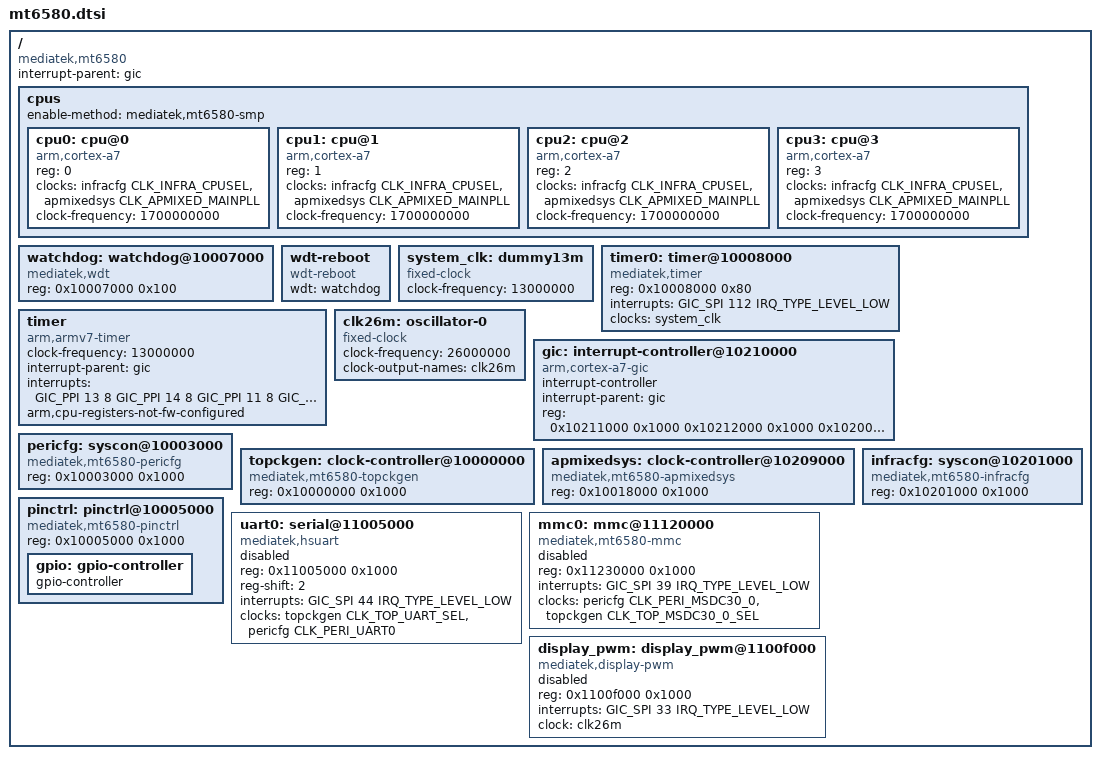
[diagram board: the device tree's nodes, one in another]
#include <dt-bindings/clock/mt6580-clk.h>
#include <dt-bindings/gpio/gpio.h>
#include <dt-bindings/interrupt-controller/irq.h>
#include <dt-bindings/interrupt-controller/arm-gic.h>
#include <dt-bindings/phy/phy.h>
#include <dt-bindings/power/mt6580-power.h>
#include <dt-bindings/reset/mt6580-reset.h>
#include "skeleton.dtsi"

/ {
    compatible = "mediatek,mt6580";
    interrupt-parent = <&gic>;
    #address-cells = <1>;
    #size-cells = <1>;

    cpus {
        #address-cells = <1>;
        #size-cells = <0>;
        enable-method = "mediatek,mt6580-smp";

        cpu0: cpu@0 {
            device_type = "cpu";
            compatible = "arm,cortex-a7";
            reg = <0>;
            clocks = <&infracfg CLK_INFRA_CPUSEL>,
                    <&apmixedsys CLK_APMIXED_MAINPLL>;
            clock-names = "cpu", "intermediate";
            clock-frequency = <1700000000>;
        };

        cpu1: cpu@1 {
            device_type = "cpu";
            compatible = "arm,cortex-a7";
            reg = <1>;
            clocks = <&infracfg CLK_INFRA_CPUSEL>,
                    <&apmixedsys CLK_APMIXED_MAINPLL>;
            clock-names = "cpu", "intermediate";
            clock-frequency = <1700000000>;
        };

        cpu2: cpu@2 {
            device_type = "cpu";
            compatible = "arm,cortex-a7";
            reg = <2>;
            clocks = <&infracfg CLK_INFRA_CPUSEL>,
                    <&apmixedsys CLK_APMIXED_MAINPLL>;
            clock-names = "cpu", "intermediate";
            clock-frequency = <1700000000>;
        };

        cpu3: cpu@3 {
            device_type = "cpu";
            compatible = "arm,cortex-a7";
            reg = <3>;
            clocks = <&infracfg CLK_INFRA_CPUSEL>,
                    <&apmixedsys CLK_APMIXED_MAINPLL>;
            clock-names = "cpu", "intermediate";
            clock-frequency = <1700000000>;
        };
    };


    watchdog: watchdog@10007000 {
        compatible = "mediatek,wdt";
        reg = <0x10007000 0x100>;
    };

    wdt-reboot {
        compatible = "wdt-reboot";
        wdt = <&watchdog>;
    };

    system_clk: dummy13m {
        compatible = "fixed-clock";
        clock-frequency = <13000000>;
        #clock-cells = <0>;
    };

    timer0: timer@10008000 {
        compatible = "mediatek,timer";
        reg = <0x10008000 0x80>;
        interrupts = <GIC_SPI 112 IRQ_TYPE_LEVEL_LOW>;
        clocks = <&system_clk>;
        clock-names = "system-clk";
    };

    timer {
        clock-frequency = <13000000>;
        compatible = "arm,armv7-timer";
        interrupt-parent = <&gic>;
        interrupts = <
                        GIC_PPI 13 8
                        GIC_PPI 14 8
                        GIC_PPI 11 8
                        GIC_PPI 10 8>;
        arm,cpu-registers-not-fw-configured;
    };

    clk26m: oscillator-0 {
        compatible = "fixed-clock";
        #clock-cells = <0>;
        clock-frequency = <26000000>;
        clock-output-names = "clk26m";
    };

    gic: interrupt-controller@10210000 {
        #address-cells = <0>;
        #interrupt-cells = <3>;
        compatible = "arm,cortex-a7-gic";
        interrupt-controller;
        interrupt-parent = <&gic>;
        reg = <
                0x10211000 0x1000
                0x10212000 0x1000
                0x10200100 0x1000>;
    };

    pericfg: syscon@10003000 {
        compatible = "mediatek,mt6580-pericfg", "syscon";
        reg = <0x10003000 0x1000>;
        #clock-cells = <1>;
    };

    topckgen: clock-controller@10000000 {
        compatible = "mediatek,mt6580-topckgen";
        reg = <0x10000000 0x1000>;
        #clock-cells = <1>;
    };

    apmixedsys: clock-controller@10209000 {
        compatible = "mediatek,mt6580-apmixedsys";
        reg = <0x10018000 0x1000>;
        #clock-cells = <1>;
    };

    infracfg: syscon@10201000 {
        compatible = "mediatek,mt6580-infracfg",
                        "syscon";
        reg = <0x10201000 0x1000>;
        #clock-cells = <1>;
        #reset-cells = <1>;
    };


    pinctrl: pinctrl@10005000 {
        compatible = "mediatek,mt6580-pinctrl";
        reg = <0x10005000 0x1000>;

        gpio: gpio-controller {
            gpio-controller;
            #gpio-cells = <2>;
        };
    };

    uart0: serial@11005000 {
        compatible = "mediatek,hsuart";
        reg = <0x11005000 0x1000>;
        reg-shift = <2>;
        interrupts = <GIC_SPI 44 IRQ_TYPE_LEVEL_LOW>;
        clocks = <&topckgen CLK_TOP_UART_SEL>,
                 <&pericfg CLK_PERI_UART0>;
        clock-names = "baud", "bus";
        status = "disabled";
    };

    mmc0: mmc@11120000 {
        compatible = "mediatek,mt6580-mmc";
        reg = <0x11230000 0x1000>;
        interrupts = <GIC_SPI 39 IRQ_TYPE_LEVEL_LOW>;
        clocks = <&pericfg CLK_PERI_MSDC30_0>,
                <&topckgen CLK_TOP_MSDC30_0_SEL>;
        clock-names = "source", "hclk";
        status = "disabled";
    };

    display_pwm: display_pwm@1100f000  {
        compatible = "mediatek,display-pwm";
        reg = <0x1100f000 0x1000>;
        interrupts = <GIC_SPI 33 IRQ_TYPE_LEVEL_LOW>;
        clock = <&clk26m>;
        status = "disabled";
    };
};
